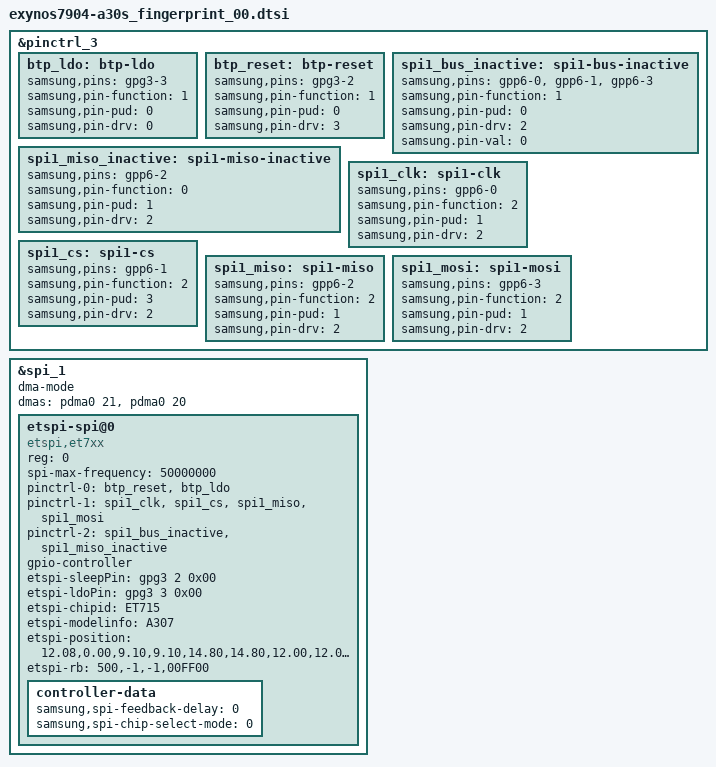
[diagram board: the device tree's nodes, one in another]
/*
 * Copyright (c) 2019, The Linux Foundation. All rights reserved.
 *
 * This program is free software; you can redistribute it and/or modify
 * it under the terms of the GNU General Public License version 2 and
 * only version 2 as published by the Free Software Foundation.
 *
 * This program is distributed in the hope that it will be useful,
 * but WITHOUT ANY WARRANTY; without even the implied warranty of
 * MERCHANTABILITY or FITNESS FOR A PARTICULAR PURPOSE.  See the
 * GNU General Public License for more details.
 */

&pinctrl_3 {
	btp_ldo: btp-ldo {
		samsung,pins = "gpg3-3";
		samsung,pin-function = <1>;
		samsung,pin-pud = <0>;
		samsung,pin-drv = <0>;
	};

	btp_reset: btp-reset {
		samsung,pins = "gpg3-2";
		samsung,pin-function = <1>;
		samsung,pin-pud = <0>;
		samsung,pin-drv = <3>;
	};

	/* SPI_FP */
	spi1_bus_inactive: spi1-bus-inactive {
		samsung,pins = "gpp6-0", "gpp6-1", "gpp6-3";
		samsung,pin-function = <1>;
		samsung,pin-pud = <0>;
		samsung,pin-drv = <2>;
		samsung.pin-val = <0>;
	};

	spi1_miso_inactive: spi1-miso-inactive {
		samsung,pins = "gpp6-2";
		samsung,pin-function = <0>;
		samsung,pin-pud = <1>;
		samsung,pin-drv = <2>;
	};

	spi1_clk: spi1-clk {
		samsung,pins = "gpp6-0";
		samsung,pin-function = <2>;
		samsung,pin-pud = <1>;
		samsung,pin-drv = <2>;
	};

	spi1_cs: spi1-cs {
		samsung,pins = "gpp6-1";
		samsung,pin-function = <2>;
		samsung,pin-pud = <3>;
		samsung,pin-drv = <2>;
	};

	spi1_miso: spi1-miso {
		samsung,pins = "gpp6-2";
		samsung,pin-function = <2>;
		samsung,pin-pud = <1>;
		samsung,pin-drv = <2>;
	};

	spi1_mosi: spi1-mosi {
		samsung,pins = "gpp6-3";
		samsung,pin-function = <2>;
		samsung,pin-pud = <1>;
		samsung,pin-drv = <2>;
	};
};

&spi_1 {
	status = "okay";

	dma-mode;
	dmas = <&pdma0 21
		&pdma0 20>;

	etspi-spi@0 {
		compatible = "etspi,et7xx";
		reg = <0>;
		spi-max-frequency = <50000000>;
		pinctrl-names = "default", "pins_poweron", "pins_poweroff";
		pinctrl-0 = <&btp_reset &btp_ldo>;
		pinctrl-1 = <&spi1_clk &spi1_cs &spi1_miso &spi1_mosi>;
		pinctrl-2 = <&spi1_bus_inactive &spi1_miso_inactive>;

		gpio-controller;
		#gpio-cells = <2>;

		etspi-sleepPin = <&gpg3 2 0x00>;
		etspi-ldoPin = <&gpg3 3 0x00>;
		etspi-chipid = "ET715";
		etspi-modelinfo = "A307";
		etspi-position = "12.08,0.00,9.10,9.10,14.80,14.80,12.00,12.00,5.00";
		etspi-rb = "500,-1,-1,00FF00";

		controller-data {
			samsung,spi-feedback-delay = <0>;
			samsung,spi-chip-select-mode = <0>;
		};
	};
};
